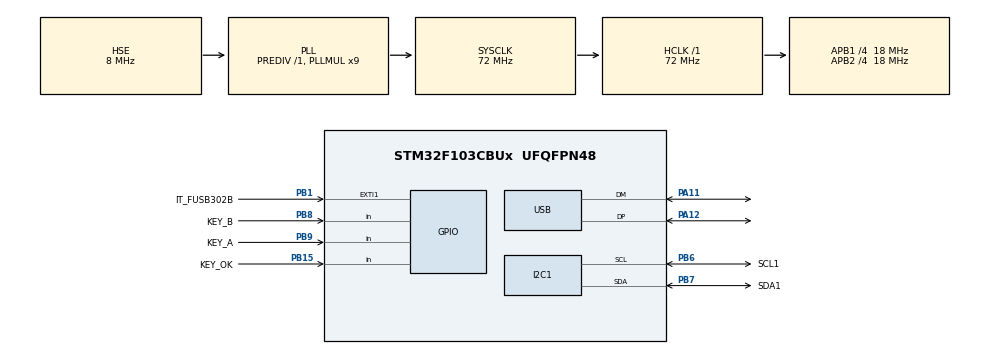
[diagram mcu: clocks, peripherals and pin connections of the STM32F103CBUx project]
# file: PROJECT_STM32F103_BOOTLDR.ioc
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Dma.I2C1_RX.0.Direction=DMA_PERIPH_TO_MEMORY
Dma.I2C1_RX.0.Instance=DMA1_Channel7
Dma.I2C1_RX.0.MemDataAlignment=DMA_MDATAALIGN_BYTE
Dma.I2C1_RX.0.MemInc=DMA_MINC_ENABLE
Dma.I2C1_RX.0.Mode=DMA_NORMAL
Dma.I2C1_RX.0.PeriphDataAlignment=DMA_PDATAALIGN_BYTE
Dma.I2C1_RX.0.PeriphInc=DMA_PINC_DISABLE
Dma.I2C1_RX.0.Priority=DMA_PRIORITY_LOW
Dma.I2C1_TX.1.Direction=DMA_MEMORY_TO_PERIPH
Dma.I2C1_TX.1.Instance=DMA1_Channel6
Dma.I2C1_TX.1.MemDataAlignment=DMA_MDATAALIGN_BYTE
Dma.I2C1_TX.1.MemInc=DMA_MINC_ENABLE
Dma.I2C1_TX.1.Mode=DMA_NORMAL
Dma.I2C1_TX.1.PeriphDataAlignment=DMA_PDATAALIGN_BYTE
Dma.I2C1_TX.1.PeriphInc=DMA_PINC_DISABLE
Dma.I2C1_TX.1.Priority=DMA_PRIORITY_MEDIUM
Dma.Request0=I2C1_RX
Dma.Request1=I2C1_TX
I2C1.I2C_Mode=I2C_Fast
Mcu.Family=STM32F1
Mcu.Name=STM32F103CBUx
Mcu.Package=UFQFPN48
Mcu.UserConstants=TREF_TEMP_ADC1_CHANNEL,ADC_CHANNEL_2;TREF_TEMP_ADC2_CHANNEL,ADC_CHANNEL_2;TEMP_TEMP_ADC1_CHANNEL,ADC_CHANNEL_7;TEMP_TEMP_ADC2_CHANNEL,ADC_CHANNEL_7;TIM1_PSC_FAST_PWM,40267;TIM1_PSC_SLOW_PWM,63379;BUZZER_CHANNEL,TIM_CHANNEL_2
NVIC.DMA1_Channel6_IRQn=true\:5\:0\:true\:false\:true\:false\:true
NVIC.DMA1_Channel7_IRQn=true\:5\:0\:true\:false\:true\:false\:true
NVIC.I2C1_ER_IRQn=true\:15\:0\:true\:false\:true\:true\:true
NVIC.I2C1_EV_IRQn=true\:15\:0\:true\:false\:true\:true\:true
NVIC.PVD_IRQn=true\:0\:0\:false\:false\:true\:true\:true
NVIC.PriorityGroup=NVIC_PRIORITYGROUP_4
NVIC.TIM4_IRQn=true\:0\:0\:false\:false\:true\:false\:true
NVIC.TimeBase=TIM4_IRQn
NVIC.TimeBaseIP=TIM4
NVIC.USB_LP_CAN1_RX0_IRQn=true\:15\:0\:true\:false\:true\:false\:true
PA11.Mode=Device
PA11.Signal=USB_DM
PA12.Mode=Device
PA12.Signal=USB_DP
PA13.Mode=Serial_Wire
PA13.Signal=SYS_JTMS-SWDIO
PA14.Mode=Serial_Wire
PA14.Signal=SYS_JTCK-SWCLK
PB1.GPIO_Label=IT_FUSB302B
PB1.GPIO_ModeDefaultEXTI=GPIO_MODE_IT_FALLING
PB1.GPIO_PuPd=GPIO_PULLUP
PB1.Signal=GPXTI1
PB15.GPIO_Label=KEY_OK
PB15.GPIO_PuPd=GPIO_PULLUP
PB15.Signal=GPIO_Input
PB6.GPIO_Label=SCL1
PB6.Mode=I2C
PB6.Signal=I2C1_SCL
PB7.GPIO_Label=SDA1
PB7.Mode=I2C
PB7.Signal=I2C1_SDA
PB8.GPIO_Label=KEY_B
PB8.GPIO_PuPd=GPIO_NOPULL
PB8.Signal=GPIO_Input
PB9.GPIO_Label=KEY_A
PB9.GPIO_PuPd=GPIO_PULLUP
PB9.Signal=GPIO_Input
PD0-OSC_IN.Mode=HSE-External-Oscillator
PD0-OSC_IN.Signal=RCC_OSC_IN
PD1-OSC_OUT.Mode=HSE-External-Oscillator
PD1-OSC_OUT.Signal=RCC_OSC_OUT
ProjectManager.HeapSize=0x300
ProjectManager.StackSize=0x400
ProjectManager.TargetToolchain=STM32CubeIDE
RCC.AHBFreq_Value=72000000
RCC.APB1CLKDivider=RCC_HCLK_DIV4
RCC.APB1Freq_Value=18000000
RCC.APB1TimFreq_Value=36000000
RCC.APB2CLKDivider=RCC_HCLK_DIV4
RCC.APB2Freq_Value=18000000
RCC.APB2TimFreq_Value=36000000
RCC.HCLKFreq_Value=72000000
RCC.PLLMUL=RCC_PLL_MUL9
RCC.PLLSourceVirtual=RCC_PLLSOURCE_HSE
RCC.SYSCLKFreq_VALUE=72000000
RCC.SYSCLKSource=RCC_SYSCLKSOURCE_PLLCLK
RCC.USBFreq_Value=48000000
RCC.USBPrescaler=RCC_USBCLKSOURCE_PLL_DIV1_5
USB_DEVICE.CLASS_NAME_FS=DFU
USB_DEVICE.USBD_DFU_APP_DEFAULT_ADD=0x08009000
USB_DEVICE.USBD_DFU_MEDIA=@Internal Flash   /0x08000000/36*001Ka,90*001Kg,02*001Kg
USB_DEVICE.VirtualMode=Dfu
USB_DEVICE.VirtualModeFS=Dfu_FS
VP_SYS_VS_tim4.Mode=TIM4
VP_USB_DEVICE_VS_USB_DEVICE_DFU_FS.Mode=DFU_FS
board=custom

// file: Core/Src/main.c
/* USER CODE BEGIN Header */
/**
  ******************************************************************************
  * @file           : main.c
  * @brief          : Main program body
  ******************************************************************************
  * @attention
  *
  * <h2><center>&copy; Copyright (c) 2021 STMicroelectronics.
  * All rights reserved.</center></h2>
  *
  * This software component is licensed by ST under BSD 3-Clause license,
  * the "License"; You may not use this file except in compliance with the
  * License. You may obtain a copy of the License at:
  *                        opensource.org/licenses/BSD-3-Clause
  *
  ******************************************************************************
  */
/* USER CODE END Header */
#include "main.h"
#include "usb_device.h"

/* USER CODE BEGIN Includes */
#include "cppports.h"
#include "usbd_dfu_if.h"
/* USER CODE END Includes */

I2C_HandleTypeDef hi2c1;
DMA_HandleTypeDef hdma_i2c1_rx;
DMA_HandleTypeDef hdma_i2c1_tx;

void SystemClock_Config(void);
static void MX_GPIO_Init(void);
static void MX_DMA_Init(void);
static void MX_I2C1_Init(void);

int main(void)
{

  /* MCU Configuration--------------------------------------------------------*/

  /* Reset of all peripherals, Initializes the Flash interface and the Systick. */
  HAL_Init();

  /* Configure the system clock */
  SystemClock_Config();

  /* Initialize all configured peripherals */
  MX_GPIO_Init();
  MX_DMA_Init();
  MX_I2C1_Init();
  /* USER CODE BEGIN 2 */
  resetWatchdog();
  //USB_Status_Init();	//复位USB引脚
  resetWatchdog();
  doGUIWork();
  /* USER CODE END 2 */

  /* Infinite loop */
  while (1)
  {

  }
}

void SystemClock_Config(void)
{
  RCC_OscInitTypeDef RCC_OscInitStruct = {0};
  RCC_ClkInitTypeDef RCC_ClkInitStruct = {0};
  RCC_PeriphCLKInitTypeDef PeriphClkInit = {0};

  /** Initializes the RCC Oscillators according to the specified parameters
  * in the RCC_OscInitTypeDef structure.
  */
  RCC_OscInitStruct.OscillatorType = RCC_OSCILLATORTYPE_HSE;
  RCC_OscInitStruct.HSEState = RCC_HSE_ON;
  RCC_OscInitStruct.HSEPredivValue = RCC_HSE_PREDIV_DIV1;
  RCC_OscInitStruct.HSIState = RCC_HSI_ON;
  RCC_OscInitStruct.PLL.PLLState = RCC_PLL_ON;
  RCC_OscInitStruct.PLL.PLLSource = RCC_PLLSOURCE_HSE;
  RCC_OscInitStruct.PLL.PLLMUL = RCC_PLL_MUL9;
  if (HAL_RCC_OscConfig(&RCC_OscInitStruct) != HAL_OK)
  {
    Error_Handler();
  }
  /** Initializes the CPU, AHB and APB buses clocks
  */
  RCC_ClkInitStruct.ClockType = RCC_CLOCKTYPE_HCLK|RCC_CLOCKTYPE_SYSCLK
                              |RCC_CLOCKTYPE_PCLK1|RCC_CLOCKTYPE_PCLK2;
  RCC_ClkInitStruct.SYSCLKSource = RCC_SYSCLKSOURCE_PLLCLK;
  RCC_ClkInitStruct.AHBCLKDivider = RCC_SYSCLK_DIV1;
  RCC_ClkInitStruct.APB1CLKDivider = RCC_HCLK_DIV4;
  RCC_ClkInitStruct.APB2CLKDivider = RCC_HCLK_DIV4;

  if (HAL_RCC_ClockConfig(&RCC_ClkInitStruct, FLASH_LATENCY_2) != HAL_OK)
  {
    Error_Handler();
  }
  PeriphClkInit.PeriphClockSelection = RCC_PERIPHCLK_USB;
  PeriphClkInit.UsbClockSelection = RCC_USBCLKSOURCE_PLL_DIV1_5;
  if (HAL_RCCEx_PeriphCLKConfig(&PeriphClkInit) != HAL_OK)
  {
    Error_Handler();
  }
}

static void MX_I2C1_Init(void)
{

  hi2c1.Instance = I2C1;
  hi2c1.Init.ClockSpeed = 400000;
  hi2c1.Init.DutyCycle = I2C_DUTYCYCLE_2;
  hi2c1.Init.OwnAddress1 = 0;
  hi2c1.Init.AddressingMode = I2C_ADDRESSINGMODE_7BIT;
  hi2c1.Init.DualAddressMode = I2C_DUALADDRESS_DISABLE;
  hi2c1.Init.OwnAddress2 = 0;
  hi2c1.Init.GeneralCallMode = I2C_GENERALCALL_DISABLE;
  hi2c1.Init.NoStretchMode = I2C_NOSTRETCH_DISABLE;
  if (HAL_I2C_Init(&hi2c1) != HAL_OK)
  {
    Error_Handler();
  }

}

static void MX_DMA_Init(void)
{

  /* DMA controller clock enable */
  __HAL_RCC_DMA1_CLK_ENABLE();

  /* DMA interrupt init */
  /* DMA1_Channel6_IRQn interrupt configuration */
  HAL_NVIC_SetPriority(DMA1_Channel6_IRQn, 5, 0);
  HAL_NVIC_EnableIRQ(DMA1_Channel6_IRQn);
  /* DMA1_Channel7_IRQn interrupt configuration */
  HAL_NVIC_SetPriority(DMA1_Channel7_IRQn, 5, 0);
  HAL_NVIC_EnableIRQ(DMA1_Channel7_IRQn);

}

static void MX_GPIO_Init(void)
{
  GPIO_InitTypeDef GPIO_InitStruct = {0};

  /* GPIO Ports Clock Enable */
  __HAL_RCC_GPIOD_CLK_ENABLE();
  __HAL_RCC_GPIOB_CLK_ENABLE();
  __HAL_RCC_GPIOA_CLK_ENABLE();

  /*Configure GPIO pin : IT_FUSB302B_Pin */
  GPIO_InitStruct.Pin = IT_FUSB302B_Pin;
  GPIO_InitStruct.Mode = GPIO_MODE_IT_FALLING;
  GPIO_InitStruct.Pull = GPIO_PULLUP;
  HAL_GPIO_Init(IT_FUSB302B_GPIO_Port, &GPIO_InitStruct);

  /*Configure GPIO pins : KEY_OK_Pin KEY_A_Pin */
  GPIO_InitStruct.Pin = KEY_OK_Pin|KEY_A_Pin;
  GPIO_InitStruct.Mode = GPIO_MODE_INPUT;
  GPIO_InitStruct.Pull = GPIO_PULLUP;
  HAL_GPIO_Init(GPIOB, &GPIO_InitStruct);

  /*Configure GPIO pin : KEY_B_Pin */
  GPIO_InitStruct.Pin = KEY_B_Pin;
  GPIO_InitStruct.Mode = GPIO_MODE_INPUT;
  GPIO_InitStruct.Pull = GPIO_NOPULL;
  HAL_GPIO_Init(KEY_B_GPIO_Port, &GPIO_InitStruct);

}

/* USER CODE BEGIN 4 */
void resetWatchdog() {
	//若没有MX_IWG_Init()，使用下面这句，会使flash不能正常储存
	//HAL_IWDG_Refresh(&hiwdg);
	;
}
/* USER CODE END 4 */

void HAL_TIM_PeriodElapsedCallback(TIM_HandleTypeDef *htim)
{
  if (htim->Instance == TIM4) {
    HAL_IncTick();
  }
}

void Error_Handler(void)
{
}

/************************ (C) COPYRIGHT STMicroelectronics *****END OF FILE****/
